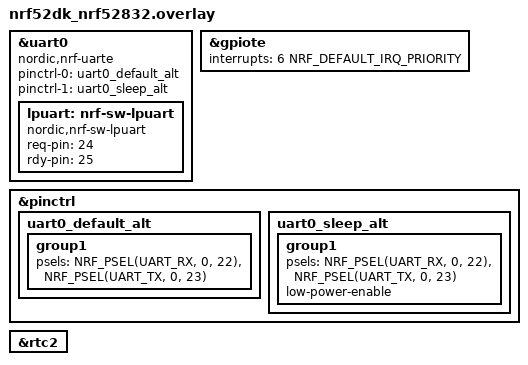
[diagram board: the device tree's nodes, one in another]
/* SPDX-License-Identifier: LicenseRef-Nordic-5-Clause */

&uart0 {
	compatible = "nordic,nrf-uarte";

	pinctrl-0 = <&uart0_default_alt>;
	pinctrl-1 = <&uart0_sleep_alt>;
	pinctrl-names = "default", "sleep";
	lpuart: nrf-sw-lpuart {
		compatible = "nordic,nrf-sw-lpuart";
		status = "okay";
		req-pin = <24>;
		rdy-pin = <25>;
	};
};

&gpiote {
	interrupts = <6 NRF_DEFAULT_IRQ_PRIORITY>;
};

&pinctrl {
	uart0_default_alt: uart0_default_alt {
		group1 {
			psels = <NRF_PSEL(UART_RX, 0, 22)>,
				<NRF_PSEL(UART_TX, 0, 23)>;
		};
	};

	uart0_sleep_alt: uart0_sleep_alt {
		group1 {
			psels = <NRF_PSEL(UART_RX, 0, 22)>,
				<NRF_PSEL(UART_TX, 0, 23)>;
			low-power-enable;
		};
	};

};

&rtc2 {
	status = "okay";
};
